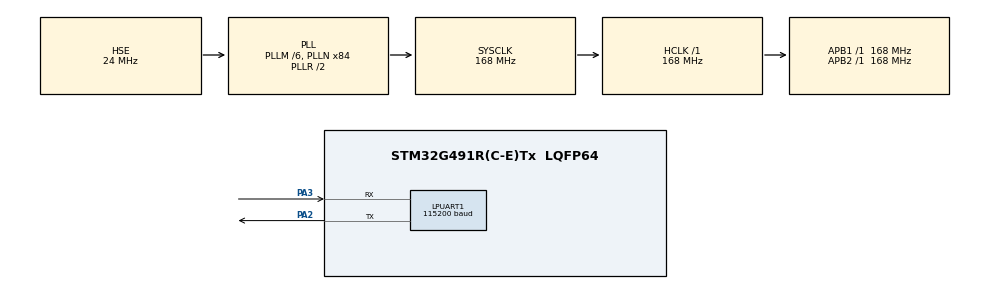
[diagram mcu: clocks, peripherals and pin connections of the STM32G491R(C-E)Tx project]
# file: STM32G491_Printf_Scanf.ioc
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LPUART1.BaudRate=115200
Mcu.Family=STM32G4
Mcu.Name=STM32G491R(C-E)Tx
Mcu.Package=LQFP64
NVIC.PriorityGroup=NVIC_PRIORITYGROUP_4
PA2.Mode=Asynchronous
PA2.Signal=LPUART1_TX
PA3.Mode=Asynchronous
PA3.Signal=LPUART1_RX
PF0-OSC_IN.Mode=HSE-External-Oscillator
PF0-OSC_IN.Signal=RCC_OSC_IN
PF1-OSC_OUT.Mode=HSE-External-Oscillator
PF1-OSC_OUT.Signal=RCC_OSC_OUT
ProjectManager.HeapSize=0x200
ProjectManager.StackSize=0x400
ProjectManager.TargetToolchain=STM32CubeIDE
RCC.ADC12Freq_Value=168000000
RCC.ADC345Freq_Value=168000000
RCC.AHBFreq_Value=168000000
RCC.APB1Freq_Value=168000000
RCC.APB1TimFreq_Value=168000000
RCC.APB2Freq_Value=168000000
RCC.APB2TimFreq_Value=168000000
RCC.CortexFreq_Value=168000000
RCC.EXTERNAL_CLOCK_VALUE=12288000
RCC.HCLKFreq_Value=168000000
RCC.HSE_VALUE=24000000
RCC.HSI48_VALUE=48000000
RCC.HSI_VALUE=16000000
RCC.LSE_VALUE=32768
RCC.PLLM=RCC_PLLM_DIV6
RCC.PLLN=84
RCC.PLLSourceVirtual=RCC_PLLSOURCE_HSE
RCC.SYSCLKFreq_VALUE=168000000
RCC.SYSCLKSource=RCC_SYSCLKSOURCE_PLLCLK
RCC.USBFreq_Value=48000000
RCC.VCOOutputFreq_Value=336000000
board=custom

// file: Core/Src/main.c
/* USER CODE BEGIN Header */
/**
  ******************************************************************************
  * @file           : main.c
  * @brief          : Main program body
  ******************************************************************************
  * @attention
  *
  * Copyright (c) 2022 STMicroelectronics.
  * All rights reserved.
  *
  * This software is licensed under terms that can be found in the LICENSE file
  * in the root directory of this software component.
  * If no LICENSE file comes with this software, it is provided AS-IS.
  *
  ******************************************************************************
  */

/**
  ******************************************************************************
  * @file       : main.c
  * @brief      : Simple printf/scanf implementation
  ******************************************************************************
  * @author     : Eugene Kalosha <kevmn07@gmail.com>
  * @version    : 1.0.0
  ******************************************************************************
  * @section License
  * SPDX-License-Identifier: GPL-3.0-or-later
  *
  * Copyright (C) 2022 Eugene Kalosha. All rights reserved.
  *
  * This program is free software; you can redistribute it and/or
  * modify it under the terms of the GNU General Public License
  * as published by the Free Software Foundation; either version 3
  * of the License, or (at your option) any later version.
  *
  * This program is distributed in the hope that it will be useful,
  * but WITHOUT ANY WARRANTY; without even the implied warranty of
  * MERCHANTABILITY or FITNESS FOR A PARTICULAR PURPOSE.  See the
  * GNU General Public License for more details.
  *
  * You should have received a copy of the GNU General Public License
  * along with this program.  If not, see <https://www.gnu.org/licenses/>.
  */
/* USER CODE END Header */
#include "main.h"

/* USER CODE BEGIN Includes */
#include <string.h>

/* USER CODE END Includes */

/* USER CODE BEGIN PD */
#ifdef __GNUC__
  /* With GCC, small printf (option LD Linker->Libraries->Small printf
     set to 'Yes') calls __io_putchar() */
  #define PUTCHAR_PROTOTYPE int __io_putchar(int ch)
  #define GETCHAR_PROTOTYPE int __io_getchar(void)
#else
  #define PUTCHAR_PROTOTYPE int fputc(int ch, FILE *f)
  #define GETCHAR_PROTOTYPE int fgetc(FILE *f)
#endif /* __GNUC__ */

/* USER CODE END PD */

UART_HandleTypeDef hlpuart1;

void SystemClock_Config(void);
static void MX_GPIO_Init(void);
static void MX_LPUART1_UART_Init(void);
/* USER CODE BEGIN PFP */

PUTCHAR_PROTOTYPE
{
  HAL_UART_Transmit(&hlpuart1, (uint8_t *)&ch, 1, HAL_MAX_DELAY);
  return ch;
}

GETCHAR_PROTOTYPE
{
  uint8_t ch = 0;

  /* Clear the Overrun flag just before receiving the first character */
  __HAL_UART_CLEAR_OREFLAG(&hlpuart1);

  /* Wait for reception of a character on the USART RX line */
  HAL_UART_Receive(&hlpuart1, (uint8_t *)&ch, 1, HAL_MAX_DELAY);
  /* Note, no echo because of polling */
  /* HAL_UART_Transmit(&hlpuart1, (uint8_t *)&ch, 1, HAL_MAX_DELAY); */
  return ch;
}

/* USER CODE END PFP */

int main(void)
{
  /* USER CODE BEGIN 1 */
	uint8_t t_str[64] = {1};
	char t_char;
	int t_int;
	float t_float;

  /* USER CODE END 1 */

  /* MCU Configuration--------------------------------------------------------*/

  /* Reset of all peripherals, Initializes the Flash interface and the Systick. */
  HAL_Init();

  /* Configure the system clock */
  SystemClock_Config();

  /* Initialize all configured peripherals */
  MX_GPIO_Init();
  MX_LPUART1_UART_Init();
  /* USER CODE BEGIN 2 */
  setvbuf(stdin, NULL, _IONBF, 0);

  /* USER CODE END 2 */

  /* Infinite loop */
  /* USER CODE BEGIN WHILE */
  printf("NUCLEO-G491RE board is ready to transfer data through LPUART1 interface\r\n");
  while (1)
  {

    /* USER CODE END WHILE */

    /* USER CODE BEGIN 3 */
	  memset (t_str, 0x00, sizeof(t_str));

	  /* delimiter */
	  printf("\r\n*\t*\t*\r\n");

	  /* string */
	  printf("Insert a string, maximum %d characters:\r\n", 63);
	  scanf("%63s", t_str);
	  printf("\r\nReceived string:\r\n%s\r\n", t_str);

	  /* char */
	  printf("Insert char:\r\n");
	  scanf("%c", &t_char);
	  printf("\r\nNote that scanf can be tricky!\r\n");
	  printf("Received char:\r\n%c, hex: %#x\r\n", t_char, (uint8_t)t_char);

	  printf("Let's try again.\r\n");
	  printf("Insert char:\r\n");
	  scanf("%c", &t_char);
	  printf("\r\nReceived char:\r\n%c, hex: %#x\r\n", t_char, (uint8_t)t_char);

	  /* integer */
	  printf("Insert integer:\r\n");
	  scanf("%d", &t_int);
 	  printf("\r\nReceived integer:\r\n%d\r\n", t_int);

	  /* float */
	  printf("Insert float:\r\n");
	  scanf("%f", &t_float);
	  printf("\r\nReceived float:\r\n%f\r\n", t_float);

  }
  /* USER CODE END 3 */
}

void SystemClock_Config(void)
{
  RCC_OscInitTypeDef RCC_OscInitStruct = {0};
  RCC_ClkInitTypeDef RCC_ClkInitStruct = {0};

  /** Configure the main internal regulator output voltage
  */
  HAL_PWREx_ControlVoltageScaling(PWR_REGULATOR_VOLTAGE_SCALE1_BOOST);

  /** Initializes the RCC Oscillators according to the specified parameters
  * in the RCC_OscInitTypeDef structure.
  */
  RCC_OscInitStruct.OscillatorType = RCC_OSCILLATORTYPE_HSE;
  RCC_OscInitStruct.HSEState = RCC_HSE_ON;
  RCC_OscInitStruct.PLL.PLLState = RCC_PLL_ON;
  RCC_OscInitStruct.PLL.PLLSource = RCC_PLLSOURCE_HSE;
  RCC_OscInitStruct.PLL.PLLM = RCC_PLLM_DIV6;
  RCC_OscInitStruct.PLL.PLLN = 84;
  RCC_OscInitStruct.PLL.PLLP = RCC_PLLP_DIV2;
  RCC_OscInitStruct.PLL.PLLQ = RCC_PLLQ_DIV2;
  RCC_OscInitStruct.PLL.PLLR = RCC_PLLR_DIV2;
  if (HAL_RCC_OscConfig(&RCC_OscInitStruct) != HAL_OK)
  {
    Error_Handler();
  }

  /** Initializes the CPU, AHB and APB buses clocks
  */
  RCC_ClkInitStruct.ClockType = RCC_CLOCKTYPE_HCLK|RCC_CLOCKTYPE_SYSCLK
                              |RCC_CLOCKTYPE_PCLK1|RCC_CLOCKTYPE_PCLK2;
  RCC_ClkInitStruct.SYSCLKSource = RCC_SYSCLKSOURCE_PLLCLK;
  RCC_ClkInitStruct.AHBCLKDivider = RCC_SYSCLK_DIV1;
  RCC_ClkInitStruct.APB1CLKDivider = RCC_HCLK_DIV1;
  RCC_ClkInitStruct.APB2CLKDivider = RCC_HCLK_DIV1;

  if (HAL_RCC_ClockConfig(&RCC_ClkInitStruct, FLASH_LATENCY_4) != HAL_OK)
  {
    Error_Handler();
  }
}

static void MX_LPUART1_UART_Init(void)
{

  hlpuart1.Instance = LPUART1;
  hlpuart1.Init.BaudRate = 115200;
  hlpuart1.Init.WordLength = UART_WORDLENGTH_8B;
  hlpuart1.Init.StopBits = UART_STOPBITS_1;
  hlpuart1.Init.Parity = UART_PARITY_NONE;
  hlpuart1.Init.Mode = UART_MODE_TX_RX;
  hlpuart1.Init.HwFlowCtl = UART_HWCONTROL_NONE;
  hlpuart1.Init.OneBitSampling = UART_ONE_BIT_SAMPLE_DISABLE;
  hlpuart1.Init.ClockPrescaler = UART_PRESCALER_DIV1;
  hlpuart1.AdvancedInit.AdvFeatureInit = UART_ADVFEATURE_NO_INIT;
  if (HAL_UART_Init(&hlpuart1) != HAL_OK)
  {
    Error_Handler();
  }
  if (HAL_UARTEx_SetTxFifoThreshold(&hlpuart1, UART_TXFIFO_THRESHOLD_1_8) != HAL_OK)
  {
    Error_Handler();
  }
  if (HAL_UARTEx_SetRxFifoThreshold(&hlpuart1, UART_RXFIFO_THRESHOLD_1_8) != HAL_OK)
  {
    Error_Handler();
  }
  if (HAL_UARTEx_DisableFifoMode(&hlpuart1) != HAL_OK)
  {
    Error_Handler();
  }

}

static void MX_GPIO_Init(void)
{

  /* GPIO Ports Clock Enable */
  __HAL_RCC_GPIOF_CLK_ENABLE();
  __HAL_RCC_GPIOA_CLK_ENABLE();

}

void Error_Handler(void)
{
  __disable_irq();
  while (1)
  {
  }
}
